# GD32W515 register map
File version: 1.0
CPU: CM33 r0p4, little endian, MPU, FPU, 4 interrupt priority bits
Registers are 32-bit, read-write, reset 0x0 unless marked. A register's access mark holds for its fields unless they carry their own. Offsets are from the block's base; [hi:lo] are bit positions; {n}, {i} and the like mark numbered series.

## EFUSE
Base 0x40022800
Same registers: SEC_EFUSE 0x50022800
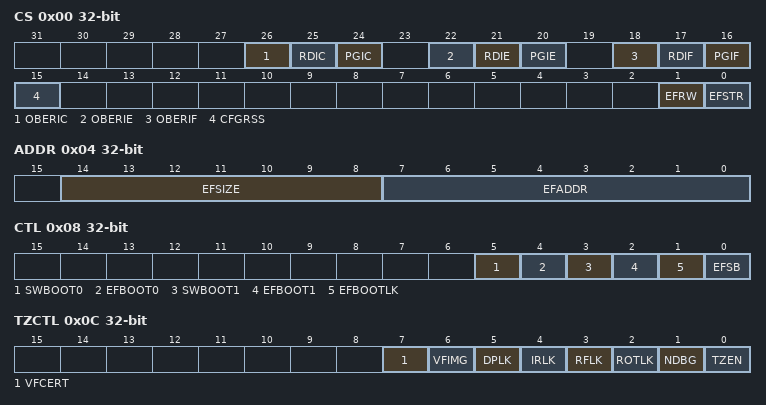
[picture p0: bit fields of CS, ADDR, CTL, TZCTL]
0x00 CS access per field — Control and status register
  [26] OBERIC rw — Clear bit for overstep boundary error interrupt flag
  [25] RDIC rw — Clear bit for read operation completed interrupt flag
  [24] PGIC rw — Clear bit for program operation completed interrupt flag
  [22] OBERIE rw — Enable bit for overstep boundary error interrupt
  [21] RDIE rw — Enable bit for read operation completed interrupt
  [20] PGIE rw — Enable bit for program operation completed interrupt
  [18] OBERIF ro — Overstep boundary error flag
  [17] RDIF ro — Read operation complete flag
  [16] PGIF ro — Program operation completed flag
  [15] CFGRSS ro — EFUSE_IAK_RSS register contribute configuer
  [1] EFRW rw — The selection of efuse operation
  [0] EFSTR rw — Start efuse operation
0x04 ADDR — Address register
  [14:8] EFSIZE — Read or write efuse data size
  [7:0] EFADDR — Read or write efuse data start address
0x08 CTL — Control register
  [5] SWBOOT0 — Efuse boot 0 bit enable
  [4] EFBOOT0 — Efuse boot0
  [3] SWBOOT1 — Efuse boot 1 bit enable
  [2] EFBOOT1 — Efuse boot1
  [1] EFBOOTLK — EFUSE_CTL register bit[5:2] lock bit
  [0] EFSB — Boot from Secure boot
0x0C TZCTL — Trustzone control register
  [7] VFCERT — Verify firmware certificate
  [6] VFIMG — Verify firmware image
  [5] DPLK — EFUSE_DP register lock bit
  [4] IRLK — EFUSE_IAK_RSS register lock bit
  [3] RFLK — EFUSE_RF_DATA register lock bit
  [2] ROTLK — EFUSE_ROTPK_KEY register lock bit
  [1] NDBG — Debugging permission setting
  [0] TZEN — Trust zone enable bit
0x10 FP_CTL — Flash protection control register
  [7:0] FP — Efuse flash protection value
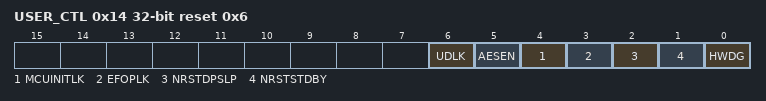
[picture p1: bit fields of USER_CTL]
0x14 USER_CTL ro reset 0x6 — User byte control register
  [6] UDLK — EFUSE_USER_DATA register lock bit
  [5] AESEN — Lock EFUSE_AES_KEY register and enable AES decrypt function
  [4] MCUINITLK — EFUSE_MCU_INIT_DATA register lock bit
  [3] EFOPLK — EFUSE_FP_CTL and EFUSE_USER_CTL register lock bit
  [2] NRSTDPSLP — Reset option of entry deep sleep mode
  [1] NRSTSTDBY — Reset option of entry standby mode
  [0] HWDG — Free watchdog timer selection
{0x18+4i} MCU_INIT_DATA{i} (i=0..2) — Mcu initialization data register{i}
  [31:0] INITDATA — Efuse mcu_init value
{0x24+4i} AES_KEY{i} (i=0..3) — Firmware AES key register {i}
  [31:0] AESKEY — Efuse AES key value.
{0x34+4i} ROTPK_KEY{i} (i=0..7) — RoTPK key register {i}
  [31:0] RKEY — Efuse RoTPK or its hash value.
0x54 DP0 — Debug password register 0
  [31:0] DP — Efuse Debug password value
0x58 DP1 — Debug password register 1
  [31:0] DP — Efuse Debug password value
{0x5C+4i} IAK_RSS{i} (i=0..15) — IAK key or RSS register {i}
  [31:0] IAKRSS — Efuse IAK/RSS value
{0x9C+4i} PUID{i} ro (i=0..3) — Product UID register {i}
  [31:0] UID — Efuse MCU UID value.
{0xAC+4i} HUK_KEY{i} ro (i=0..3) — HUK key register {i}
  [31:0] HKEY — Efuse HUK value
0xBC RF_DATA0 — RF data register
  [31:0] HKEY — Efuse HUK value
{0xBC+4i} RF_DATA{i} (i=1..11) — RF data register {i}
  [31:0] RFDATA — Efuse RF data value
{0xEC+4i} USER_DATA{i} (i=0..7) — User data register {i}
  [31:0] USERDATA — Efuse USER_DATA value.
0x118 PRE_TZEN — EFUSE Pre-TZEN register
  [0] STZEN — Enable Trustzone function by software
0x120 TZ_BOOT_ADDR ro — TrustZone boot address register
  [31:0] TZBOOTADDR — Boot from the address when TrustZone is enabled
0x124 NTZ_BOOT_ADDR ro — No-TrustZone boot address register
  [31:0] NTZBOOTADDR — Boot from the address when TrustZone is disabled

## EXTI — External interrupt/event controller
Base 0x40013C00
Same registers: SEC_EXTI 0x50013C00
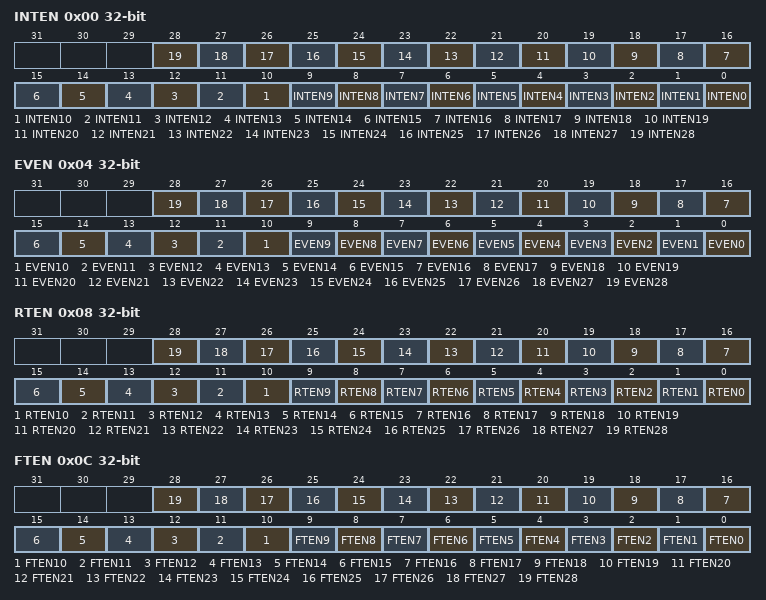
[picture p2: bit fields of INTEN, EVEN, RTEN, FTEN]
0x00 INTEN — Interrupt enable register (EXTI_INTEN)
  [n] INTEN{n} (n=0..28) — Enable Interrupt on line {n}
0x04 EVEN — Event enable register (EXTI_EVEN)
  [n] EVEN{n} (n=0..28) — Enable Event on line {n}
0x08 RTEN — Rising Edge Trigger Enable register (EXTI_RTEN)
  [n] RTEN{n} (n=0..28) — Rising edge trigger enable of line {n}
0x0C FTEN — Falling Egde Trigger Enable register (EXTI_FTEN)
  [n] FTEN{n} (n=0..28) — Falling edge trigger enable of line {n}
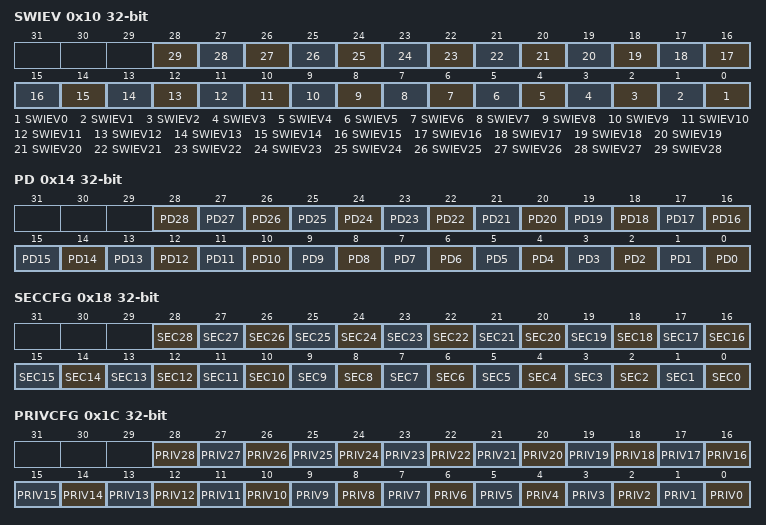
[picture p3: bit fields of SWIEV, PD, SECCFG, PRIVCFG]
0x10 SWIEV — Software interrupt event register (EXTI_SWIEV)
  [n] SWIEV{n} (n=0..28) — Interrupt/Event software trigger on line {n}
0x14 PD — Pending register (EXTI_PD)
  [n] PD{n} (n=0..28) — Interrupt pending status of line {n}
0x18 SECCFG — EXTI security configuration register
  [n] SEC{n} (n=0..28) — Security enable on event input {n}
0x1C PRIVCFG — EXTI privilege configuration register
  [n] PRIV{n} (n=0..28) — Security enable on event input {n}
0x20 LOCK — EXTI lock register
  [0] LOCK — Global security and privilege configuration registers
